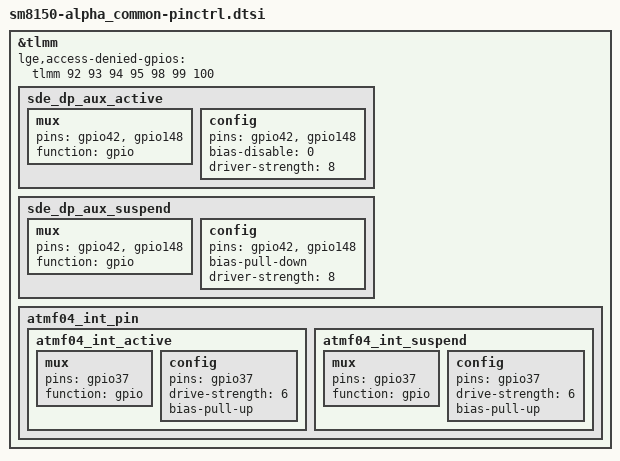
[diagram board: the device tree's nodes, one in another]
/*
 * Copyright (c) 2018, The Linux Foundation. All rights reserved.
 *
 * This program is free software; you can redistribute it and/or modify
 * it under the terms of the GNU General Public License version 2 and
 * only version 2 as published by the Free Software Foundation.
 *
 * This program is distributed in the hope that it will be useful,
 * but WITHOUT ANY WARRANTY; without even the implied warranty of
 * MERCHANTABILITY or FITNESS FOR A PARTICULAR PURPOSE.  See the
 * GNU General Public License for more details.
 */

#include "../../sm8150_common/sm8150_common-pinctrl.dtsi"

&tlmm {
	lge,access-denied-gpios = <&tlmm 92 93 94 95 98 99 100 101>;

	sde_dp_aux_active:sde_dp_aux_active {
		mux {
			pins = "gpio42", "gpio148";
			function = "gpio";
		};

		config {
			pins = "gpio42", "gpio148";
			bias-disable = <0>;
			driver-strength = <8>;
		};
	};

	sde_dp_aux_suspend:sde_dp_aux_suspend {
		mux {
			pins = "gpio42", "gpio148";
			function = "gpio";
		};

		config {
			pins = "gpio42", "gpio148";
			bias-pull-down;
			driver-strength = <8>;
		};
	};

	atmf04_int_pin {
		atmf04_int_active: atmf04_int_active {
			mux {
				pins = "gpio37";
				function = "gpio";
			};
			config {
				pins = "gpio37";
				drive-strength = <6>;   /* 6 MA */
				bias-pull-up;           /* PULL UP*/
			};
		};

		atmf04_int_suspend: atmf04_int_suspend {
			mux {
				pins = "gpio37";
				function = "gpio";
			};
			config {
				pins = "gpio37";
				drive-strength = <6>;   /* 6 MA */
				bias-pull-up;           /* PULL UP */
			};
		};
	};
};
